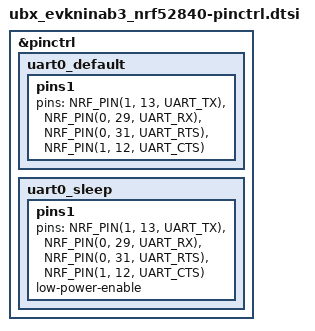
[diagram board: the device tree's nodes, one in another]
/*
 * Copyright (c) 2021 Nordic Semiconductor ASA
 * SPDX-License-Identifier: Apache-2.0
 */

&pinctrl {
	uart0_default: uart0_default {
		pins1 {
			pins = <NRF_PIN(1, 13, UART_TX)>,
			       <NRF_PIN(0, 29, UART_RX)>,
			       <NRF_PIN(0, 31, UART_RTS)>,
			       <NRF_PIN(1, 12, UART_CTS)>;
		};
	};

	uart0_sleep: uart0_sleep {
		pins1 {
			pins = <NRF_PIN(1, 13, UART_TX)>,
			       <NRF_PIN(0, 29, UART_RX)>,
			       <NRF_PIN(0, 31, UART_RTS)>,
			       <NRF_PIN(1, 12, UART_CTS)>;
			low-power-enable;
		};
	};

};
